# M04_SystemBus register map
Vendor: Babel; File version: 1.0
M04_SystemBus Register Map
CPU: CM0 r0p0, little endian, no MPU, no FPU
Registers are 32-bit, read-only, reset 0x0 unless marked. A register's access mark holds for its fields unless they carry their own. Offsets are from the block's base; lines under a group give offsets from that group; [hi:lo] are bit positions; {n}, {i} and the like mark numbered series; 'fields as' and 'values as' point back to an identical list; <NAME> marks a mode.

## Memory map
0x00000000 M04_SystemBus

## M04_SystemBus
Base 0x00000000
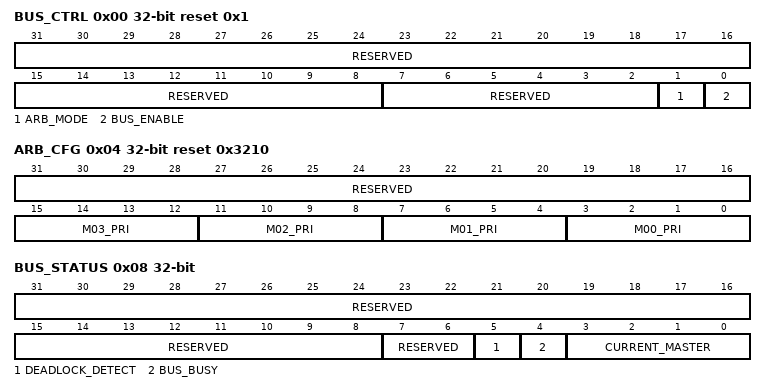
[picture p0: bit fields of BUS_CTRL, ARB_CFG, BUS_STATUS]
0x00 BUS_CTRL rw reset 0x1 — 总线控制：使能、仲裁模式
  [31:8] RESERVED - — 保留，必须写 0
  [7:2] RESERVED - — 保留，必须写 0
  [1] ARB_MODE — 仲裁模式。0=Round-Robin，1=Priority
  [0] BUS_ENABLE — 总线使能。1=使能，0=禁用
0x04 ARB_CFG rw reset 0x3210 — 仲裁优先级配置
  [31:16] RESERVED - — 保留，必须写 0
  [15:12] M03_PRI — M03 (DRAM) 优先级
  [11:8] M02_PRI — M02 (SRAM) 优先级
  [7:4] M01_PRI — M01 (Dataflow) 优先级
  [3:0] M00_PRI — M00 (Systolic) 优先级 (0=最高)
0x08 BUS_STATUS — 总线状态：当前 master、busy、deadlock
  [31:8] RESERVED - — 保留
  [7:6] RESERVED - — 保留
  [5] DEADLOCK_DETECT — 死锁检测标志
  [4] BUS_BUSY — 总线忙标志
  [3:0] CURRENT_MASTER — 当前占用总线的 Master ID
0x0C BW_COUNTER_M00 — M00 带宽计数器 (bytes/ms)
  [31:0] COUNT — M00 带宽计数 (bytes/ms)
{0xC+4i} BW_COUNTER_M{i:02} (i=1..3) — M{i:02} 带宽计数器
  [31:0] COUNT — M{i:02} 带宽计数 (bytes/ms)
